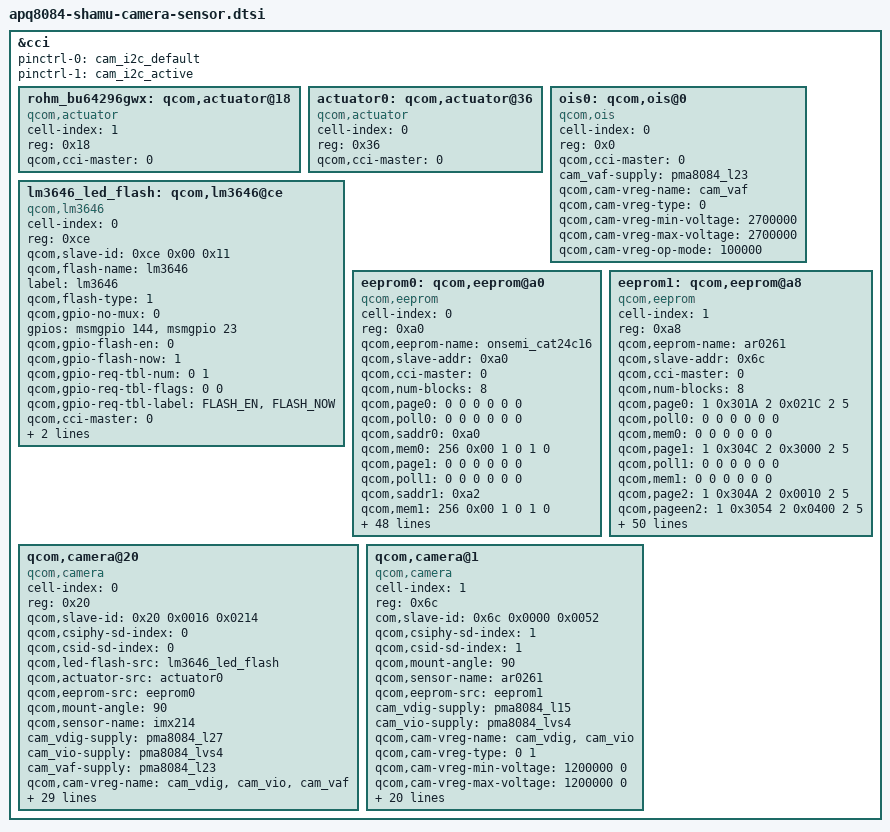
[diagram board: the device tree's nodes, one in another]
/*
 * Copyright (c) 2013, The Linux Foundation. All rights reserved.
 *
 * This program is free software; you can redistribute it and/or modify
 * it under the terms of the GNU General Public License version 2 and
 * only version 2 as published by the Free Software Foundation.
 *
 * This program is distributed in the hope that it will be useful,
 * but WITHOUT ANY WARRANTY; without even the implied warranty of
 * MERCHANTABILITY or FITNESS FOR A PARTICULAR PURPOSE.  See the
 * GNU General Public License for more details.
 */

&cci {
	pinctrl-names = "default", "active";
	pinctrl-0 = <&cam_i2c_default>;
	pinctrl-1 = <&cam_i2c_active>;

	rohm_bu64296gwx: qcom,actuator@18 {
		cell-index = <1>;
		reg = <0x18>;
		compatible = "qcom,actuator";
		qcom,cci-master = <0>;
	};

	actuator0: qcom,actuator@36 {
		cell-index = <0>;
		reg = <0x36>;
		compatible = "qcom,actuator";
		qcom,cci-master = <0>;
	};

		ois0: qcom,ois@0 {
		cell-index = <0>;
		reg = <0x0>;
		compatible = "qcom,ois";
		qcom,cci-master = <0>;
		cam_vaf-supply = <&pma8084_l23>;
		qcom,cam-vreg-name = "cam_vaf";
		qcom,cam-vreg-type = <0>;
		qcom,cam-vreg-min-voltage = <2700000>;
		qcom,cam-vreg-max-voltage = <2700000>;
		qcom,cam-vreg-op-mode = <100000>;
		};

	lm3646_led_flash: qcom,lm3646@ce {
		cell-index = <0>;
		reg = <0xce>;
		qcom,slave-id = <0xce 0x00 0x11>;
		compatible = "qcom,lm3646";
		qcom,flash-name = "lm3646";
		label = "lm3646";
		qcom,flash-type = <1>;
		qcom,gpio-no-mux = <0>;
		gpios = <&msmgpio 144 0>,
			<&msmgpio 23 0>;
		qcom,gpio-flash-en = <0>;
		qcom,gpio-flash-now = <1>;
		qcom,gpio-req-tbl-num = <0 1>;
		qcom,gpio-req-tbl-flags = <0 0>;
		qcom,gpio-req-tbl-label = "FLASH_EN",
				"FLASH_NOW";
		qcom,cci-master = <0>;
		pinctrl-names = "default", "active";
		pinctrl-0 = <&cam_flash_default>;
		pinctrl-1 = <&cam_flash_active>;
	};

	eeprom0: qcom,eeprom@a0 {
		cell-index = <0>;
		reg = <0xa0>;
		qcom,eeprom-name = "onsemi_cat24c16";
		compatible = "qcom,eeprom";
		qcom,slave-addr = <0xa0>;
		qcom,cci-master = <0>;
		qcom,num-blocks = <8>;
		qcom,page0 = <0 0 0 0 0 0>;
		qcom,poll0 = <0 0 0 0 0 0>;
		qcom,saddr0 = <0xa0>;
		qcom,mem0 = <256 0x00 1 0 1 0>;

		qcom,page1 = <0 0 0 0 0 0>;
		qcom,poll1 = <0 0 0 0 0 0>;
		qcom,saddr1 = <0xa2>;
		qcom,mem1 = <256 0x00 1 0 1 0>;

		qcom,page2 = <0 0 0 0 0 0>;
		qcom,poll2 = <0 0 0 0 0 0>;
		qcom,saddr2 = <0xa4>;
		qcom,mem2 = <256 0x00 1 0 1 0>;

		qcom,page3 = <0 0 0 0 0 0>;
		qcom,poll3 = <0 0 0 0 0 0>;
		qcom,saddr3 = <0xa6>;
		qcom,mem3 = <256 0x00 1 0 1 0>;

		qcom,page4 = <0 0 0 0 0 0>;
		qcom,poll4 = <0 0 0 0 0 0>;
		qcom,saddr4 = <0xa8>;
		qcom,mem4 = <256 0x00 1 0 1 0>;

		qcom,page5 = <0 0 0 0 0 0>;
		qcom,poll5 = <0 0 0 0 0 0>;
		qcom,saddr5 = <0xaa>;
		qcom,mem5 = <256 0x00 1 0 1 0>;

		qcom,page6 = <0 0 0 0 0 0>;
		qcom,poll6 = <0 0 0 0 0 0>;
		qcom,saddr6 = <0xac>;
		qcom,mem6 = <256 0x00 1 0 1 0>;

		qcom,page7 = <0 0 0 0 0 0>;
		qcom,poll7 = <0 0 0 0 0 0>;
		qcom,saddr7 = <0xae>;
		qcom,mem7 = <112 0x00 1 0 1 0>;

		cam_vdig-supply = <&pma8084_l27>;
		cam_vio-supply = <&pma8084_lvs4>;
		qcom,cam-vreg-name = "cam_vdig", "cam_vio";
		qcom,cam-vreg-type = <0 1>;
		qcom,cam-vreg-min-voltage = <1050000 0>;
		qcom,cam-vreg-max-voltage = <1050000 0>;
		qcom,cam-vreg-op-mode = <105000 0 100000>;
		qcom,gpio-no-mux = <0>;
		gpios = <&msmgpio 125 0>;
		qcom,gpio-vio = <0>;
		qcom,gpio-req-tbl-num = <0>;
		qcom,gpio-req-tbl-flags = <1>;
		qcom,gpio-req-tbl-label = "CAM_VIO";
		qcom,gpio-set-tbl-num = <1>;
		qcom,gpio-set-tbl-flags = <0>;
		qcom,gpio-set-tbl-delay = <1000>;
		qcom,cam-power-seq-type = "sensor_vreg", "sensor_vreg",
				"sensor_gpio";
		qcom,cam-power-seq-val = "cam_vdig", "cam_vio", "sensor_gpio_vio";
		qcom,cam-power-seq-cfg-val = <1 1 1>;
		qcom,cam-power-seq-delay = <1 1 1>;
		status = "ok";
		pinctrl-names = "default", "active";
		pinctrl-0 = <&eeprom_ctrl_default>;
		pinctrl-1 = <&eeprom_ctrl_active>;
	};

  eeprom1: qcom,eeprom@a8 {
		cell-index = <1>;
		reg = <0xa8>;
		qcom,eeprom-name = "ar0261";
		compatible = "qcom,eeprom";
		qcom,slave-addr = <0x6c>;
		qcom,cci-master = <0>;
		qcom,num-blocks = <8>;

		qcom,page0 = <1 0x301A 2 0x021C 2 5>;
		qcom,poll0 = <0 0 0 0 0 0>;
		qcom,mem0 =  <0 0 0 0 0 0>;

		qcom,page1 = <1 0x304C 2 0x3000 2 5>;
		qcom,poll1 = <0 0 0 0 0 0>;
		qcom,mem1 =  <0 0 0 0 0 0>;

		qcom,page2 = <1 0x304A 2 0x0010 2 5>;
		qcom,pageen2 = <1 0x3054 2 0x0400 2 5>;
		qcom,poll2 = <1 0x304A 2 0x40 2 5>;
		qcom,mem2 = <50 0x3800 2 0 1 0>;

		qcom,page3 = <1 0x304C 2 0x3100 2 5>;
		qcom,poll3 = <0 0 0 0 0 0>;
		qcom,mem3 =  <0 0 0 0 0 0>;

		qcom,page4 = <1 0x304A 2 0x0010 2 5>;
		qcom,pageen4 = <1 0x3054 2 0x0400 2 5>;
		qcom,poll4 = <1 0x304A 2 0x40 2 5>;
		qcom,mem4 = <50 0x3800 2 0 1 0>;

		qcom,page5 = <1 0x304C 2 0x3200 2 5>;
		qcom,poll5 = <0 0 0 0 0 0>;
		qcom,mem5 =  <0 0 0 0 0 0>;

		qcom,page6 = <1 0x304A 2 0x0010 2 5>;
		qcom,pageen6 = <1 0x3054 2 0x0400 2 5>;
		qcom,poll6 = <1 0x304A 2 0x40 2 5>;
		qcom,mem6 = <50 0x3800 2 0 1 0>;

		qcom,page7 = <1 0x301A 2 0x0218 2 5>;
		qcom,poll7 = <0 0 0 0 0 0>;
		qcom,mem7 =  <0 0 0 0 0 0>;

		cam_vdig-supply = <&pma8084_l15>;
		cam_vio-supply = <&pma8084_lvs4>;
		qcom,cam-vreg-name = "cam_vdig", "cam_vio";
		qcom,cam-vreg-type = <0 1>;
		qcom,cam-vreg-min-voltage = <1200000 0>;
		qcom,cam-vreg-max-voltage = <1200000 0>;
		qcom,cam-vreg-op-mode = <105000 0>;

		qcom,gpio-no-mux = <0>;
		gpios = <&msmgpio 17 0>,
			<&msmgpio 38 0>,
			<&msmgpio 37 0>;
		qcom,gpio-reset = <1>;
		qcom,gpio-vana = <2>;
		qcom,gpio-req-tbl-num = <0 1 2>;
		qcom,gpio-req-tbl-flags = <1 0 0>;
		qcom,gpio-req-tbl-label = "CAMIF_MCLK",
					"CAM_RESET",
					"CAM_AVDD";

		qcom,cam-power-seq-type = "sensor_vreg", "sensor_gpio", "sensor_vreg",
			"sensor_clk" , "sensor_gpio";
		qcom,cam-power-seq-val = "cam_vio", "sensor_gpio_vana", "cam_vdig",
			"sensor_cam_mclk", "sensor_gpio_reset";
		qcom,cam-power-seq-cfg-val = <1 1 1 24000000 1>;
		qcom,cam-power-seq-delay = <10 10 10 15 20>;

		qcom,gpio-set-tbl-num = <1 1>;
		qcom,gpio-set-tbl-flags = <0 2>;
		qcom,gpio-set-tbl-delay = <1000 4000>;
		qcom,csi-lane-assign = <0x4320>;
		qcom,csi-lane-mask = <0x07>;
		pinctrl-names = "default", "active";
		pinctrl-0 = <&cam_mclk2_default &cam2_ctrl_default>;
		pinctrl-1 = <&cam_mclk2_active &cam2_ctrl_active>;
	};

	qcom,camera@20 {
		cell-index = <0>;
		compatible = "qcom,camera";
		reg = <0x20>;
		qcom,slave-id = <0x20 0x0016 0x0214>;
		qcom,csiphy-sd-index = <0>;
		qcom,csid-sd-index = <0>;
		qcom,led-flash-src = <&lm3646_led_flash>;
		qcom,actuator-src = <&actuator0>;
		qcom,eeprom-src = <&eeprom0>;
		qcom,mount-angle = <90>;
		qcom,sensor-name = "imx214";
		cam_vdig-supply = <&pma8084_l27>;
		cam_vio-supply = <&pma8084_lvs4>;
		cam_vaf-supply = <&pma8084_l23>;
		qcom,cam-vreg-name = "cam_vdig", "cam_vio", "cam_vaf";
		qcom,cam-vreg-type = <0 1 0>;
		qcom,cam-vreg-min-voltage = <1050000 0 2700000>;
		qcom,cam-vreg-max-voltage = <1050000 0 2700000>;
		qcom,cam-vreg-op-mode = <105000 0 100000>;
		qcom,gpio-no-mux = <0>;
		gpios = <&msmgpio 15 0>,
                        <&msmgpio 26 0>,
			<&msmgpio 35 0>,
			<&msmgpio 36 0>,
			<&msmgpio 120 0>;
		qcom,gpio-vdig = <1>;
		qcom,gpio-vaf = <2>;
		qcom,gpio-reset = <3>;
		qcom,gpio-vana = <4>;
		qcom,gpio-req-tbl-num = <0 1 2 3 4>;
		qcom,gpio-req-tbl-flags = <1 0 0 0 0>;
		qcom,gpio-req-tbl-label = "CAMIF_MCLK",
				"CAM_VDIG",
				"CAM_VAF",
				"CAM_RESET1",
				"CAM_VANA";
		qcom,gpio-set-tbl-num = <1 1 1 1 1>;
		qcom,gpio-set-tbl-flags = <0 1 2 3 4>;
		qcom,gpio-set-tbl-delay = <1000 1000 30000 1000 1000>;
		qcom,csi-lane-assign = <0x4320>;
		qcom,csi-lane-mask = <0x1F>;
		qcom,sensor-position = <0>;
		qcom,sensor-mode = <0>;
		qcom,sensor-type = <0>;
		qcom,cci-master = <0>;
		status = "ok";
		pinctrl-names = "default", "active";
		pinctrl-0 = <&cam_mclk0_default &cam1_ctrl_default>;
		pinctrl-1 = <&cam_mclk0_active &cam1_ctrl_active>;
		qcom,ois-src = <&ois0>;
	};

	qcom,camera@1 {
		cell-index = <1>;
		compatible = "qcom,camera";
		reg = <0x6c>;
		com,slave-id = <0x6c 0x0000 0x0052>;
		qcom,csiphy-sd-index = <1>;
		qcom,csid-sd-index = <1>;
		qcom,mount-angle = <90>;
		qcom,sensor-name = "ar0261";
		qcom,eeprom-src = <&eeprom1>;
		cam_vdig-supply = <&pma8084_l15>;
		cam_vio-supply = <&pma8084_lvs4>;
		qcom,cam-vreg-name = "cam_vdig", "cam_vio";
		qcom,cam-vreg-type = <0 1>;
		qcom,cam-vreg-min-voltage = <1200000 0>;
		qcom,cam-vreg-max-voltage = <1200000 0>;
		qcom,cam-vreg-op-mode = <105000 0>;
		qcom,gpio-no-mux = <0>;
		gpios = <&msmgpio 17 0>,
			<&msmgpio 38 0>,
			<&msmgpio 37 0>;
		qcom,gpio-reset = <1>;
		qcom,gpio-vana = <2>;
		qcom,gpio-req-tbl-num = <0 1 2>;
		qcom,gpio-req-tbl-flags = <1 0 0>;
		qcom,gpio-req-tbl-label ="CAMIF_MCLK",
					"CAM_RESET",
					"CAM_AVDD";
		qcom,gpio-set-tbl-num = <1 1>;
		qcom,gpio-set-tbl-flags = <0 2>;
		qcom,gpio-set-tbl-delay = <1000 4000>;
		qcom,csi-lane-assign = <0x4320>;
		qcom,csi-lane-mask = <0x07>;
		qcom,sensor-position = <1>;
		qcom,sensor-mode = <1>;
		qcom,sensor-type = <0>;
		qcom,cci-master = <0>;
		status = "ok";
		pinctrl-names = "default", "active";
		pinctrl-0 = < >;
		pinctrl-1 = < >;
	};

};
